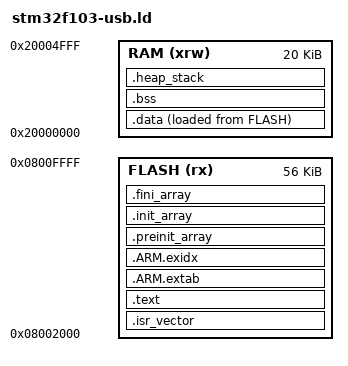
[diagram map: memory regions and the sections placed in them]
ENTRY(Reset_Handler)

MEMORY
{
  FLASH (rx)  : ORIGIN = 0x08002000, LENGTH = 56K
  RAM   (xrw) : ORIGIN = 0x20000000, LENGTH = 20K
}

_estack = ORIGIN(RAM) + LENGTH(RAM);

SECTIONS
{
  .isr_vector : { KEEP(*(.isr_vector)) } > FLASH
  .text :
  {
    *(.text .text.*)
    *(.rodata .rodata.*)
    KEEP(*(.init))
    KEEP(*(.fini))
  } > FLASH
  .ARM.extab : { *(.ARM.extab* .gnu.linkonce.armextab.*) } > FLASH
  .ARM.exidx :
  {
    __exidx_start = .;
    *(.ARM.exidx*)
    __exidx_end = .;
  } > FLASH
  .preinit_array (READONLY) :
  {
    PROVIDE_HIDDEN(__preinit_array_start = .);
    KEEP(*(.preinit_array*))
    PROVIDE_HIDDEN(__preinit_array_end = .);
  } > FLASH
  .init_array (READONLY) :
  {
    PROVIDE_HIDDEN(__init_array_start = .);
    KEEP(*(SORT_BY_INIT_PRIORITY(.init_array.*)))
    KEEP(*(.init_array))
    PROVIDE_HIDDEN(__init_array_end = .);
  } > FLASH
  .fini_array (READONLY) :
  {
    PROVIDE_HIDDEN(__fini_array_start = .);
    KEEP(*(SORT_BY_INIT_PRIORITY(.fini_array.*)))
    KEEP(*(.fini_array))
    PROVIDE_HIDDEN(__fini_array_end = .);
  } > FLASH
  .data :
  {
    . = ALIGN(4);
    _sdata = .;
    *(.data .data.*)
    . = ALIGN(4);
    _edata = .;
  } > RAM AT > FLASH
  _sidata = LOADADDR(.data);
  .bss (NOLOAD) :
  {
    . = ALIGN(4);
    _sbss = .;
    *(.bss .bss.* COMMON)
    . = ALIGN(4);
    _ebss = .;
  } > RAM
  .heap_stack (NOLOAD) :
  {
    . = ALIGN(8);
    PROVIDE(end = .);
    PROVIDE(_end = .);
    . += 0x800 + 0xA00;
  } > RAM
}
